AUTOSAR XML (schema 00052)
package /Components
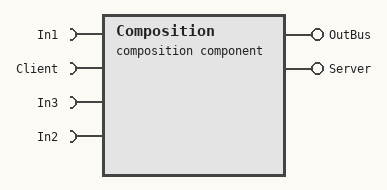
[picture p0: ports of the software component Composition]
  composition sw component type Composition
    4 x require port:
      In1
      Client
      In3
      In2
    provide port OutBus
    provide port Server
